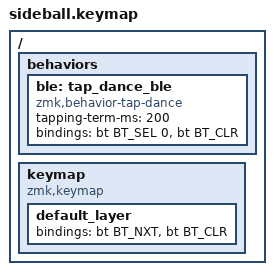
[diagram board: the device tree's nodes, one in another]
/*
 * Copyright (c) 2022 The ZMK Contributors
 *
 * SPDX-License-Identifier: MIT
 */

#include <behaviors.dtsi>
#include <dt-bindings/zmk/keys.h>
#include <dt-bindings/zmk/bt.h>
#include <dt-bindings/zmk/mouse.h>

/ {

    behaviors {
        ble: tap_dance_ble {
            compatible = "zmk,behavior-tap-dance";
            #binding-cells = <0>;
            tapping-term-ms = <200>;
            bindings = <&bt BT_SEL 0>, <&bt BT_CLR>;
        };
    };

    keymap {
        compatible = "zmk,keymap";

        default_layer {
            bindings = <&bt BT_NXT>, <&bt BT_CLR>;  // Bind the behavior to a key
        };
    };
};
